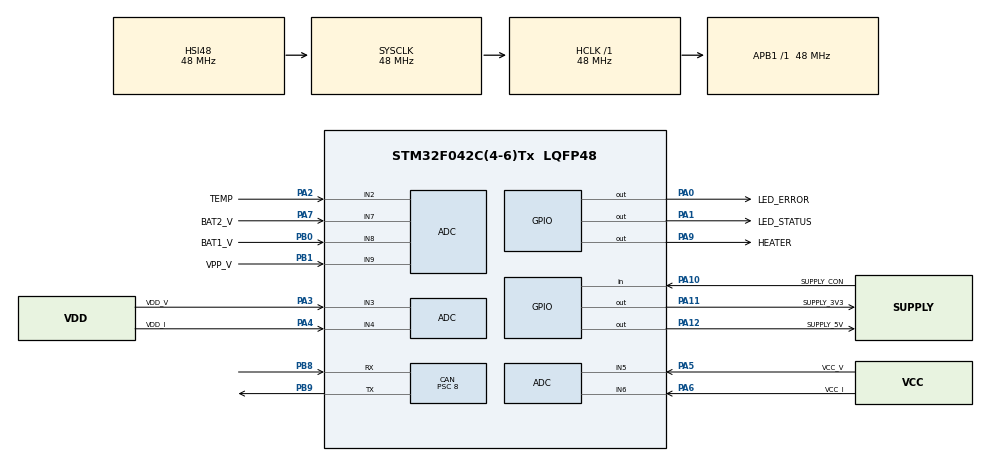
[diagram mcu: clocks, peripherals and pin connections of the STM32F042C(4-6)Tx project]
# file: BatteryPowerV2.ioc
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ADC.ClockPrescaler=ADC_CLOCK_ASYNC_DIV1
ADC.ContinuousConvMode=ENABLE
ADC.DMAContinuousRequests=ENABLE
ADC.EnableAnalogWatchDog=false
ADC.SamplingTime=ADC_SAMPLETIME_55CYCLES_5
CAN.BS1=CAN_BS1_4TQ
CAN.CalculateBaudRate=1000000
CAN.CalculateTimeBit=1000
CAN.CalculateTimeQuantum=166.66666666666666
CAN.Prescaler=8
Dma.ADC.0.Direction=DMA_PERIPH_TO_MEMORY
Dma.ADC.0.Instance=DMA1_Channel1
Dma.ADC.0.MemDataAlignment=DMA_MDATAALIGN_HALFWORD
Dma.ADC.0.MemInc=DMA_MINC_ENABLE
Dma.ADC.0.Mode=DMA_CIRCULAR
Dma.ADC.0.PeriphDataAlignment=DMA_PDATAALIGN_HALFWORD
Dma.ADC.0.PeriphInc=DMA_PINC_DISABLE
Dma.ADC.0.Priority=DMA_PRIORITY_LOW
Dma.Request0=ADC
IWDG.Prescaler=IWDG_PRESCALER_16
IWDG.Reload=4095
IWDG.Window=4095
Mcu.Family=STM32F0
Mcu.Name=STM32F042C(4-6)Tx
Mcu.Package=LQFP48
Mcu.UserConstants=SAMPLE_FREQ,1000;TLM_FREQ,10
NVIC.CEC_CAN_IRQn=true\:1\:0\:true\:false\:true\:true\:true\:true
NVIC.DMA1_Channel1_IRQn=true\:1\:0\:true\:false\:true\:false\:true\:true
NVIC.TIM14_IRQn=true\:3\:0\:true\:false\:true\:true\:true\:true
NVIC.TIM2_IRQn=true\:3\:0\:true\:false\:true\:true\:true\:true
PA0.GPIO_Label=LED_ERROR
PA0.Signal=GPIO_Output
PA1.GPIO_Label=LED_STATUS
PA1.Signal=GPIO_Output
PA10.GPIO_Label=SUPPLY_CON
PA10.Signal=GPIO_Input
PA11.GPIO_Label=SUPPLY_3V3
PA11.Signal=GPIO_Output
PA12.GPIO_Label=SUPPLY_5V
PA12.Signal=GPIO_Output
PA13.Mode=Serial_Wire
PA13.Signal=SYS_SWDIO
PA14.Mode=Serial_Wire
PA14.Signal=SYS_SWCLK
PA2.GPIO_Label=TEMP
PA2.Mode=IN2
PA2.Signal=ADC_IN2
PA3.GPIO_Label=VDD_V
PA3.Mode=IN3
PA3.Signal=ADC_IN3
PA4.GPIO_Label=VDD_I
PA4.Mode=IN4
PA4.Signal=ADC_IN4
PA5.GPIO_Label=VCC_V
PA5.Mode=IN5
PA5.Signal=ADC_IN5
PA6.GPIO_Label=VCC_I
PA6.Mode=IN6
PA6.Signal=ADC_IN6
PA7.GPIO_Label=BAT2_V
PA7.Mode=IN7
PA7.Signal=ADC_IN7
PA9.GPIO_Label=HEATER
PA9.Signal=GPIO_Output
PB0.GPIO_Label=BAT1_V
PB0.Mode=IN8
PB0.Signal=ADC_IN8
PB1.GPIO_Label=VPP_V
PB1.Mode=IN9
PB1.Signal=ADC_IN9
PB8.Mode=CAN_Activate
PB8.Signal=CAN_RX
PB9.Mode=CAN_Activate
PB9.Signal=CAN_TX
PC14OSC32_IN.Mode=LSE-External-Oscillator
PC14OSC32_IN.Signal=RCC_OSC32_IN
PC15OSC32_OUT.Mode=LSE-External-Oscillator
PC15OSC32_OUT.Signal=RCC_OSC32_OUT
ProjectManager.HeapSize=0x200
ProjectManager.StackSize=0x400
ProjectManager.TargetToolchain=STM32CubeIDE
RCC.AHBFreq_Value=48000000
RCC.APB1Freq_Value=48000000
RCC.APB1TimFreq_Value=48000000
RCC.HCLKFreq_Value=48000000
RCC.SYSCLKFreq_VALUE=48000000
RCC.SYSCLKSource=RCC_SYSCLKSOURCE_HSI48
TIM14.Period=10000/TLM_FREQ-1
TIM14.Prescaler=4800
TIM2.Period=10000/SAMPLE_FREQ-1
TIM2.Prescaler=4800
VP_ADC_TempSens_Input.Mode=IN-TempSens
VP_ADC_Vref_Input.Mode=IN-Vrefint
VP_IWDG_VS_IWDG.Mode=IWDG_Activate
VP_TIM14_VS_ClockSourceINT.Mode=Enable_Timer
VP_TIM2_VS_ClockSourceINT.Mode=Internal
board=custom

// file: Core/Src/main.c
/* USER CODE BEGIN Header */
/**
  ******************************************************************************
  * @file           : main.c
  * @brief          : Main program body
  ******************************************************************************
  * @attention
  *
  * Copyright (c) 2023 STMicroelectronics.
  * All rights reserved.
  *
  * This software is licensed under terms that can be found in the LICENSE file
  * in the root directory of this software component.
  * If no LICENSE file comes with this software, it is provided AS-IS.
  *
  ******************************************************************************
  */
/* USER CODE END Header */
#include "main.h"

/* USER CODE BEGIN Includes */
#include "app.h"
/* USER CODE END Includes */

ADC_HandleTypeDef hadc;
DMA_HandleTypeDef hdma_adc;

CAN_HandleTypeDef hcan;

IWDG_HandleTypeDef hiwdg;

TIM_HandleTypeDef htim2;
TIM_HandleTypeDef htim14;

void SystemClock_Config(void);
static void MX_GPIO_Init(void);
static void MX_DMA_Init(void);
static void MX_CAN_Init(void);
static void MX_IWDG_Init(void);
static void MX_ADC_Init(void);
static void MX_TIM2_Init(void);
static void MX_TIM14_Init(void);
/* USER CODE BEGIN PFP */
void initialise_monitor_handles(void);
/* USER CODE END PFP */

int main(void)
{
  /* USER CODE BEGIN 1 */
#ifdef DEBUG
  initialise_monitor_handles();
#endif
  /* USER CODE END 1 */

  /* MCU Configuration--------------------------------------------------------*/

  /* Reset of all peripherals, Initializes the Flash interface and the Systick. */
  HAL_Init();

  /* Configure the system clock */
  SystemClock_Config();

  /* Initialize all configured peripherals */
  MX_GPIO_Init();
  MX_DMA_Init();
  MX_CAN_Init();
  MX_IWDG_Init();
  MX_ADC_Init();
  MX_TIM2_Init();
  MX_TIM14_Init();
  /* USER CODE BEGIN 2 */

  setup();

  /* USER CODE END 2 */

  /* Infinite loop */
  while (1)
  {

    /* USER CODE BEGIN 3 */
    loop();

#ifndef DEBUG
    HAL_IWDG_Refresh(&hiwdg);
#endif
  }
  /* USER CODE END 3 */
}

void SystemClock_Config(void)
{
  RCC_OscInitTypeDef RCC_OscInitStruct = {0};
  RCC_ClkInitTypeDef RCC_ClkInitStruct = {0};

  /** Initializes the RCC Oscillators according to the specified parameters
  * in the RCC_OscInitTypeDef structure.
  */
  RCC_OscInitStruct.OscillatorType = RCC_OSCILLATORTYPE_HSI14|RCC_OSCILLATORTYPE_HSI48
                              |RCC_OSCILLATORTYPE_LSI;
  RCC_OscInitStruct.HSI48State = RCC_HSI48_ON;
  RCC_OscInitStruct.HSI14State = RCC_HSI14_ON;
  RCC_OscInitStruct.HSI14CalibrationValue = 16;
  RCC_OscInitStruct.LSIState = RCC_LSI_ON;
  RCC_OscInitStruct.PLL.PLLState = RCC_PLL_NONE;
  if (HAL_RCC_OscConfig(&RCC_OscInitStruct) != HAL_OK)
  {
    Error_Handler();
  }

  /** Initializes the CPU, AHB and APB buses clocks
  */
  RCC_ClkInitStruct.ClockType = RCC_CLOCKTYPE_HCLK|RCC_CLOCKTYPE_SYSCLK
                              |RCC_CLOCKTYPE_PCLK1;
  RCC_ClkInitStruct.SYSCLKSource = RCC_SYSCLKSOURCE_HSI48;
  RCC_ClkInitStruct.AHBCLKDivider = RCC_SYSCLK_DIV1;
  RCC_ClkInitStruct.APB1CLKDivider = RCC_HCLK_DIV1;

  if (HAL_RCC_ClockConfig(&RCC_ClkInitStruct, FLASH_LATENCY_1) != HAL_OK)
  {
    Error_Handler();
  }
}

static void MX_ADC_Init(void)
{

  ADC_ChannelConfTypeDef sConfig = {0};

  /** Configure the global features of the ADC (Clock, Resolution, Data Alignment and number of conversion)
  */
  hadc.Instance = ADC1;
  hadc.Init.ClockPrescaler = ADC_CLOCK_ASYNC_DIV1;
  hadc.Init.Resolution = ADC_RESOLUTION_12B;
  hadc.Init.DataAlign = ADC_DATAALIGN_RIGHT;
  hadc.Init.ScanConvMode = ADC_SCAN_DIRECTION_FORWARD;
  hadc.Init.EOCSelection = ADC_EOC_SINGLE_CONV;
  hadc.Init.LowPowerAutoWait = DISABLE;
  hadc.Init.LowPowerAutoPowerOff = DISABLE;
  hadc.Init.ContinuousConvMode = ENABLE;
  hadc.Init.DiscontinuousConvMode = DISABLE;
  hadc.Init.ExternalTrigConv = ADC_SOFTWARE_START;
  hadc.Init.ExternalTrigConvEdge = ADC_EXTERNALTRIGCONVEDGE_NONE;
  hadc.Init.DMAContinuousRequests = ENABLE;
  hadc.Init.Overrun = ADC_OVR_DATA_PRESERVED;
  if (HAL_ADC_Init(&hadc) != HAL_OK)
  {
    Error_Handler();
  }

  /** Configure for the selected ADC regular channel to be converted.
  */
  sConfig.Channel = ADC_CHANNEL_2;
  sConfig.Rank = ADC_RANK_CHANNEL_NUMBER;
  sConfig.SamplingTime = ADC_SAMPLETIME_55CYCLES_5;
  if (HAL_ADC_ConfigChannel(&hadc, &sConfig) != HAL_OK)
  {
    Error_Handler();
  }

  /** Configure for the selected ADC regular channel to be converted.
  */
  sConfig.Channel = ADC_CHANNEL_3;
  if (HAL_ADC_ConfigChannel(&hadc, &sConfig) != HAL_OK)
  {
    Error_Handler();
  }

  /** Configure for the selected ADC regular channel to be converted.
  */
  sConfig.Channel = ADC_CHANNEL_4;
  if (HAL_ADC_ConfigChannel(&hadc, &sConfig) != HAL_OK)
  {
    Error_Handler();
  }

  /** Configure for the selected ADC regular channel to be converted.
  */
  sConfig.Channel = ADC_CHANNEL_5;
  if (HAL_ADC_ConfigChannel(&hadc, &sConfig) != HAL_OK)
  {
    Error_Handler();
  }

  /** Configure for the selected ADC regular channel to be converted.
  */
  sConfig.Channel = ADC_CHANNEL_6;
  if (HAL_ADC_ConfigChannel(&hadc, &sConfig) != HAL_OK)
  {
    Error_Handler();
  }

  /** Configure for the selected ADC regular channel to be converted.
  */
  sConfig.Channel = ADC_CHANNEL_7;
  if (HAL_ADC_ConfigChannel(&hadc, &sConfig) != HAL_OK)
  {
    Error_Handler();
  }

  /** Configure for the selected ADC regular channel to be converted.
  */
  sConfig.Channel = ADC_CHANNEL_8;
  if (HAL_ADC_ConfigChannel(&hadc, &sConfig) != HAL_OK)
  {
    Error_Handler();
  }

  /** Configure for the selected ADC regular channel to be converted.
  */
  sConfig.Channel = ADC_CHANNEL_9;
  if (HAL_ADC_ConfigChannel(&hadc, &sConfig) != HAL_OK)
  {
    Error_Handler();
  }

  /** Configure for the selected ADC regular channel to be converted.
  */
  sConfig.Channel = ADC_CHANNEL_TEMPSENSOR;
  if (HAL_ADC_ConfigChannel(&hadc, &sConfig) != HAL_OK)
  {
    Error_Handler();
  }

  /** Configure for the selected ADC regular channel to be converted.
  */
  sConfig.Channel = ADC_CHANNEL_VREFINT;
  if (HAL_ADC_ConfigChannel(&hadc, &sConfig) != HAL_OK)
  {
    Error_Handler();
  }

}

static void MX_CAN_Init(void)
{

  hcan.Instance = CAN;
  hcan.Init.Prescaler = 8;
  hcan.Init.Mode = CAN_MODE_NORMAL;
  hcan.Init.SyncJumpWidth = CAN_SJW_1TQ;
  hcan.Init.TimeSeg1 = CAN_BS1_4TQ;
  hcan.Init.TimeSeg2 = CAN_BS2_1TQ;
  hcan.Init.TimeTriggeredMode = DISABLE;
  hcan.Init.AutoBusOff = DISABLE;
  hcan.Init.AutoWakeUp = DISABLE;
  hcan.Init.AutoRetransmission = DISABLE;
  hcan.Init.ReceiveFifoLocked = DISABLE;
  hcan.Init.TransmitFifoPriority = DISABLE;
  if (HAL_CAN_Init(&hcan) != HAL_OK)
  {
    Error_Handler();
  }

}

static void MX_IWDG_Init(void)
{

  /* USER CODE BEGIN IWDG_Init 0 */
#ifdef DEBUG
  return;
#endif
  /* USER CODE END IWDG_Init 0 */

  hiwdg.Instance = IWDG;
  hiwdg.Init.Prescaler = IWDG_PRESCALER_16;
  hiwdg.Init.Window = 4095;
  hiwdg.Init.Reload = 4095;
  if (HAL_IWDG_Init(&hiwdg) != HAL_OK)
  {
    Error_Handler();
  }

}

static void MX_TIM2_Init(void)
{

  TIM_ClockConfigTypeDef sClockSourceConfig = {0};
  TIM_MasterConfigTypeDef sMasterConfig = {0};

  htim2.Instance = TIM2;
  htim2.Init.Prescaler = 4800;
  htim2.Init.CounterMode = TIM_COUNTERMODE_UP;
  htim2.Init.Period = 10000/SAMPLE_FREQ-1;
  htim2.Init.ClockDivision = TIM_CLOCKDIVISION_DIV1;
  htim2.Init.AutoReloadPreload = TIM_AUTORELOAD_PRELOAD_DISABLE;
  if (HAL_TIM_Base_Init(&htim2) != HAL_OK)
  {
    Error_Handler();
  }
  sClockSourceConfig.ClockSource = TIM_CLOCKSOURCE_INTERNAL;
  if (HAL_TIM_ConfigClockSource(&htim2, &sClockSourceConfig) != HAL_OK)
  {
    Error_Handler();
  }
  sMasterConfig.MasterOutputTrigger = TIM_TRGO_RESET;
  sMasterConfig.MasterSlaveMode = TIM_MASTERSLAVEMODE_DISABLE;
  if (HAL_TIMEx_MasterConfigSynchronization(&htim2, &sMasterConfig) != HAL_OK)
  {
    Error_Handler();
  }

}

static void MX_TIM14_Init(void)
{

  htim14.Instance = TIM14;
  htim14.Init.Prescaler = 4800;
  htim14.Init.CounterMode = TIM_COUNTERMODE_UP;
  htim14.Init.Period = 10000/TLM_FREQ-1;
  htim14.Init.ClockDivision = TIM_CLOCKDIVISION_DIV1;
  htim14.Init.AutoReloadPreload = TIM_AUTORELOAD_PRELOAD_DISABLE;
  if (HAL_TIM_Base_Init(&htim14) != HAL_OK)
  {
    Error_Handler();
  }

}

static void MX_DMA_Init(void)
{

  /* DMA controller clock enable */
  __HAL_RCC_DMA1_CLK_ENABLE();

  /* DMA interrupt init */
  /* DMA1_Channel1_IRQn interrupt configuration */
  HAL_NVIC_SetPriority(DMA1_Channel1_IRQn, 1, 0);
  HAL_NVIC_EnableIRQ(DMA1_Channel1_IRQn);

}

static void MX_GPIO_Init(void)
{
  GPIO_InitTypeDef GPIO_InitStruct = {0};

  /* GPIO Ports Clock Enable */
  __HAL_RCC_GPIOC_CLK_ENABLE();
  __HAL_RCC_GPIOA_CLK_ENABLE();
  __HAL_RCC_GPIOB_CLK_ENABLE();

  /*Configure GPIO pin Output Level */
  HAL_GPIO_WritePin(GPIOA, LED_ERROR_Pin|LED_STATUS_Pin|HEATER_Pin|SUPPLY_3V3_Pin
                          |SUPPLY_5V_Pin, GPIO_PIN_RESET);

  /*Configure GPIO pins : LED_ERROR_Pin LED_STATUS_Pin HEATER_Pin SUPPLY_3V3_Pin
                           SUPPLY_5V_Pin */
  GPIO_InitStruct.Pin = LED_ERROR_Pin|LED_STATUS_Pin|HEATER_Pin|SUPPLY_3V3_Pin
                          |SUPPLY_5V_Pin;
  GPIO_InitStruct.Mode = GPIO_MODE_OUTPUT_PP;
  GPIO_InitStruct.Pull = GPIO_NOPULL;
  GPIO_InitStruct.Speed = GPIO_SPEED_FREQ_LOW;
  HAL_GPIO_Init(GPIOA, &GPIO_InitStruct);

  /*Configure GPIO pin : SUPPLY_CON_Pin */
  GPIO_InitStruct.Pin = SUPPLY_CON_Pin;
  GPIO_InitStruct.Mode = GPIO_MODE_INPUT;
  GPIO_InitStruct.Pull = GPIO_NOPULL;
  HAL_GPIO_Init(SUPPLY_CON_GPIO_Port, &GPIO_InitStruct);

}

void Error_Handler(void)
{
  __disable_irq();
  while (1)
  {
  }
}
